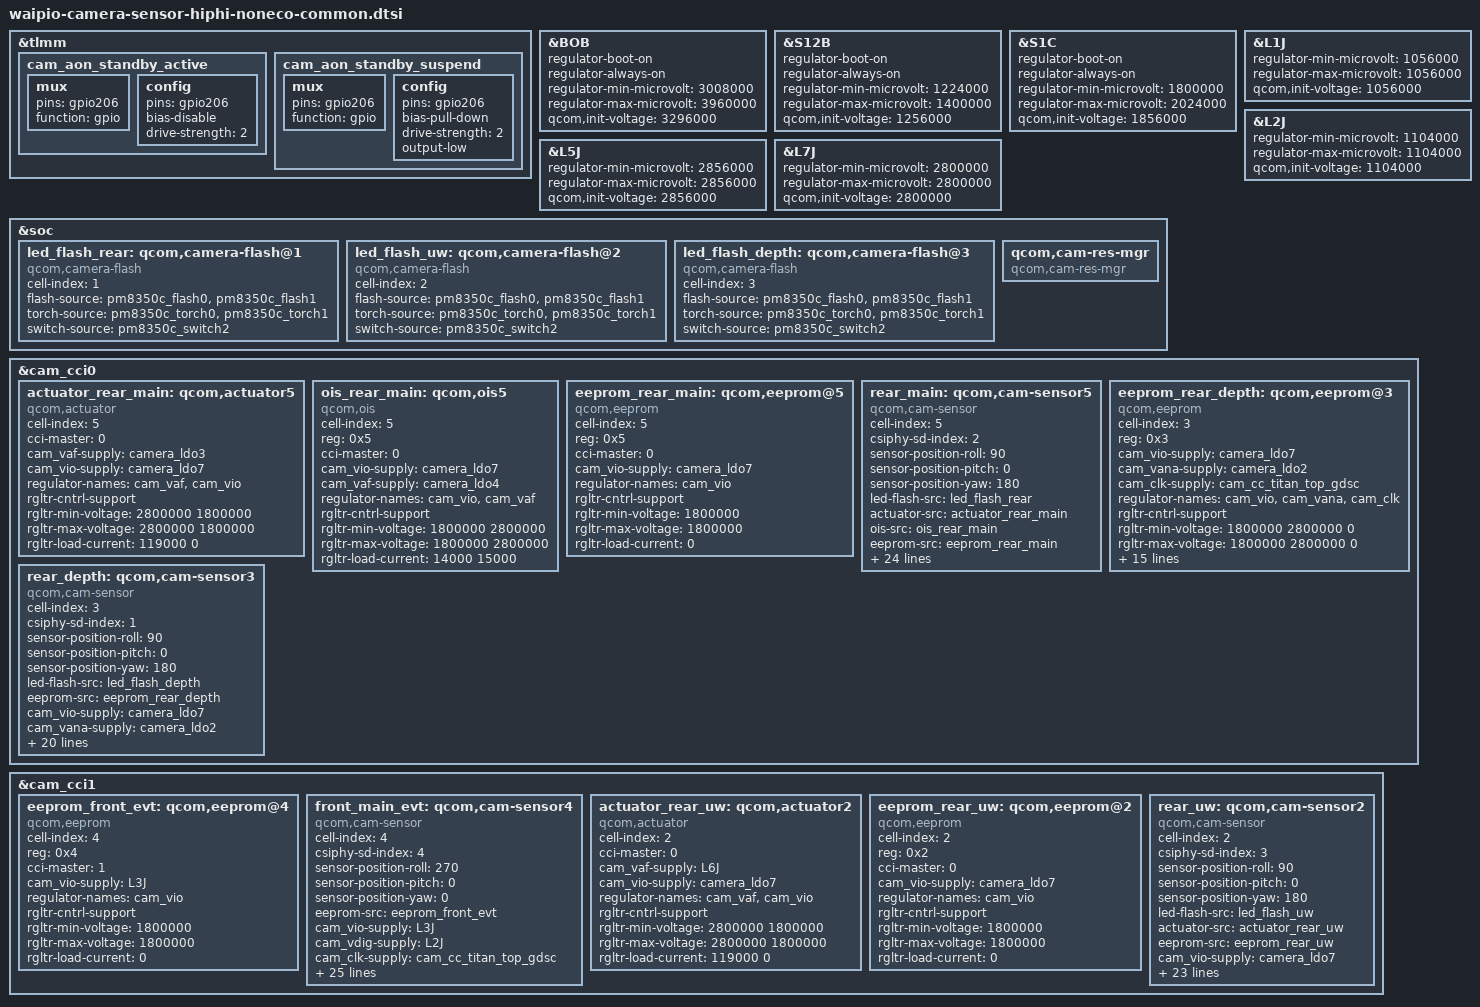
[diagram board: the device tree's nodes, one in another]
/*
   This base is original from "waipio-camera-sensor-mtp.dtsi"
*/
#include <dt-bindings/clock/qcom,camcc-waipio.h>

&tlmm {
	cam_aon_standby_active: cam_aon_standby_active {
		mux {
			pins = "gpio206";
			function = "gpio";
		};

		config {
			pins = "gpio206";
			bias-disable; /* No Pull */
			drive-strength = <2>; /* 2 MA */
		};
	};

	cam_aon_standby_suspend: cam_aon_standby_suspend {
		mux {
			pins = "gpio206";
			function = "gpio";
		};

		config {
			pins = "gpio206";
			bias-pull-down; /* Pull Down */
			drive-strength = <2>; /* 2 MA */
			output-low;
		};
	};
};

&BOB {
	regulator-boot-on;
	regulator-always-on;
	regulator-min-microvolt = <3008000>;
	regulator-max-microvolt = <3960000>;
	qcom,init-voltage = <3296000>;
	status = "ok";
};

&S12B {
	regulator-boot-on;
	regulator-always-on;
	regulator-min-microvolt = <1224000>;
	regulator-max-microvolt = <1400000>;
	qcom,init-voltage = <1256000>;
	status = "ok";
};

&S1C {
	regulator-boot-on;
	regulator-always-on;
	regulator-min-microvolt = <1800000>;
	regulator-max-microvolt = <2024000>;
	qcom,init-voltage = <1856000>;
	status = "ok";
};

&L1J {
	regulator-min-microvolt = <1056000>;
	regulator-max-microvolt = <1056000>;
	qcom,init-voltage = <1056000>;
};

&L2J {
	regulator-min-microvolt = <1104000>;
	regulator-max-microvolt = <1104000>;
	qcom,init-voltage = <1104000>;
};

&L5J {
	regulator-min-microvolt = <2856000>;
	regulator-max-microvolt = <2856000>;
	qcom,init-voltage = <2856000>;
};

&L7J {
	regulator-min-microvolt = <2800000>;
	regulator-max-microvolt = <2800000>;
	qcom,init-voltage = <2800000>;
};

&soc {
	led_flash_rear: qcom,camera-flash@1 {
		cell-index = <1>;
		compatible = "qcom,camera-flash";
		flash-source = <&pm8350c_flash0 &pm8350c_flash1>;
		torch-source = <&pm8350c_torch0 &pm8350c_torch1>;
		switch-source = <&pm8350c_switch2>;
		status = "ok";
	};

	led_flash_uw: qcom,camera-flash@2 {
		cell-index = <2>;
		compatible = "qcom,camera-flash";
		flash-source = <&pm8350c_flash0 &pm8350c_flash1>;
		torch-source = <&pm8350c_torch0 &pm8350c_torch1>;
		switch-source = <&pm8350c_switch2>;
		status = "ok";
	};

	led_flash_depth: qcom,camera-flash@3 {
		cell-index = <3>;
		compatible = "qcom,camera-flash";
		flash-source = <&pm8350c_flash0 &pm8350c_flash1>;
		torch-source = <&pm8350c_torch0 &pm8350c_torch1>;
		switch-source = <&pm8350c_switch2>;
		status = "ok";
	};

	qcom,cam-res-mgr {
		compatible = "qcom,cam-res-mgr";
		status = "ok";
	};
};

&cam_cci0 {
	actuator_rear_main: qcom,actuator5 {
		cell-index = <5>;
		compatible = "qcom,actuator";
		cci-master = <0>;
		cam_vaf-supply = <&camera_ldo3>;
		cam_vio-supply = <&camera_ldo7>;
		regulator-names = "cam_vaf", "cam_vio";
		rgltr-cntrl-support;
		rgltr-min-voltage = <2800000 1800000>;
		rgltr-max-voltage = <2800000 1800000>;
		rgltr-load-current = <119000 0>;
	};

	ois_rear_main: qcom,ois5 {
		cell-index = <5>;
		reg = <0x5>;
		compatible = "qcom,ois";
		cci-master = <0>;
		cam_vio-supply = <&camera_ldo7>;
		cam_vaf-supply = <&camera_ldo4>;
		regulator-names = "cam_vio", "cam_vaf";
		rgltr-cntrl-support;
		rgltr-min-voltage = <1800000 2800000>;
		rgltr-max-voltage = <1800000 2800000>;
		rgltr-load-current = <14000 15000>;
		status = "ok";
	};

	eeprom_rear_main: qcom,eeprom@5 {
		cell-index = <5>;
		reg = <0x5>;
		compatible = "qcom,eeprom";
		cci-master = <0>;
		cam_vio-supply = <&camera_ldo7>;
		regulator-names = "cam_vio";
		rgltr-cntrl-support;
		rgltr-min-voltage = <1800000>;
		rgltr-max-voltage = <1800000>;
		rgltr-load-current = <0>;
	};

	rear_main: qcom,cam-sensor5 {
		cell-index = <5>;
		compatible = "qcom,cam-sensor";
		csiphy-sd-index = <2>;
		sensor-position-roll = <90>;
		sensor-position-pitch = <0>;
		sensor-position-yaw = <180>;
		led-flash-src = <&led_flash_rear>;
		actuator-src = <&actuator_rear_main>;
		ois-src = <&ois_rear_main>;
		eeprom-src = <&eeprom_rear_main>;
		cam_vio-supply = <&camera_ldo7>;
		cam_vdig-supply = <&camera_ldo5>;
		cam_clk-supply = <&cam_cc_titan_top_gdsc>;
		cam_vana-supply = <&camera_ldo1>;
		regulator-names = "cam_vio", "cam_vdig",
			"cam_clk", "cam_vana";
		rgltr-cntrl-support;
		rgltr-min-voltage = <1800000 1100000 0 2800000>;
		rgltr-max-voltage = <1800000 1100000 0 2800000>;
		rgltr-load-current = <3000 675000 0 112000>;
		gpio-no-mux = <0>;
		pinctrl-names = "cam_default", "cam_suspend";
		pinctrl-0 = <&cam_sensor_mclk2_active
			&cam_sensor_active_rst2>;
		pinctrl-1 = <&cam_sensor_mclk2_suspend
			&cam_sensor_suspend_rst2>;
		gpios = <&tlmm 102 0>,
			<&tlmm 117 0>;
		gpio-reset = <1>;
		gpio-req-tbl-num = <0 1>;
		gpio-req-tbl-flags = <1 0>;
		gpio-req-tbl-label = "CAMIF_MCLK2",
					"CAM_RESET2";
		cci-master = <0>;
		clocks = <&clock_camcc CAM_CC_MCLK2_CLK>;
		clock-names = "cam_clk";
		clock-cntl-level = "nominal";
		clock-rates = <24000000>;
		status = "ok";
	};

	eeprom_rear_depth: qcom,eeprom@3 {
		cell-index = <3>;
		reg = <0x3>;
		compatible = "qcom,eeprom";
		cam_vio-supply = <&camera_ldo7>;
		cam_vana-supply = <&camera_ldo2>;
		cam_clk-supply = <&cam_cc_titan_top_gdsc>;
		regulator-names = "cam_vio", "cam_vana", "cam_clk";
		rgltr-cntrl-support;
		rgltr-min-voltage = <1800000 2800000 0>;
		rgltr-max-voltage = <1800000 2800000 0>;
		rgltr-load-current = <20000 90000 0>;
		gpio-no-mux = <0>;
		pinctrl-names = "cam_default", "cam_suspend";
		pinctrl-0 = <&cam_sensor_mclk1_active
				 &cam_sensor_active_rst1>;
		pinctrl-1 = <&cam_sensor_mclk1_suspend
				 &cam_sensor_suspend_rst1>;
		gpios = <&tlmm 101 0>,
			<&tlmm 24 0>;
		gpio-reset = <1>;
		gpio-req-tbl-num = <0 1>;
		gpio-req-tbl-flags = <1 0>;
		gpio-req-tbl-label = "CAMIF_MCLK1",
					"CAM_RESET1";
		cci-master = <1>;
		clocks = <&clock_camcc CAM_CC_MCLK1_CLK>;
		clock-names = "cam_clk";
		clock-cntl-level = "nominal";
		clock-rates = <24000000>;
	};

	rear_depth: qcom,cam-sensor3 {
		cell-index = <3>;
		compatible = "qcom,cam-sensor";
		csiphy-sd-index = <1>;
		sensor-position-roll = <90>;
		sensor-position-pitch = <0>;
		sensor-position-yaw = <180>;
		led-flash-src = <&led_flash_depth>;
		eeprom-src = <&eeprom_rear_depth>;
		cam_vio-supply = <&camera_ldo7>;
		cam_vana-supply = <&camera_ldo2>;
		cam_clk-supply = <&cam_cc_titan_top_gdsc>;
		regulator-names = "cam_vio", "cam_vana", "cam_clk";
		rgltr-cntrl-support;
		rgltr-min-voltage = <1800000 2800000 0>;
		rgltr-max-voltage = <1800000 2800000 0>;
		rgltr-load-current = <20000 90000 0>;
		gpio-no-mux = <0>;
		pinctrl-names = "cam_default", "cam_suspend";
		pinctrl-0 = <&cam_sensor_mclk1_active
				 &cam_sensor_active_rst1>;
		pinctrl-1 = <&cam_sensor_mclk1_suspend
				 &cam_sensor_suspend_rst1>;
		gpios = <&tlmm 101 0>,
			<&tlmm 24 0>;
		gpio-reset = <1>;
		gpio-req-tbl-num = <0 1>;
		gpio-req-tbl-flags = <1 0>;
		gpio-req-tbl-label = "CAMIF_MCLK1",
					"CAM_RESET1";
		cci-master = <1>;
		clocks = <&clock_camcc CAM_CC_MCLK1_CLK>;
		clock-names = "cam_clk";
		clock-cntl-level = "nominal";
		clock-rates = <24000000>;
		status = "ok";
	};
};

&cam_cci1 {
	eeprom_front_evt: qcom,eeprom@4 {
		cell-index = <4>;
		reg = <0x4>;
		compatible = "qcom,eeprom";
		cci-master = <1>;
		cam_vio-supply = <&L3J>;
		regulator-names = "cam_vio";
		rgltr-cntrl-support;
		rgltr-min-voltage = <1800000>;
		rgltr-max-voltage = <1800000>;
		rgltr-load-current = <0>;
	};

	front_main_evt: qcom,cam-sensor4 {
		cell-index = <4>;
		compatible = "qcom,cam-sensor";
		csiphy-sd-index = <4>;
		sensor-position-roll = <270>;
		sensor-position-pitch = <0>;
		sensor-position-yaw = <0>;
		eeprom-src = <&eeprom_front_evt>;
		cam_vio-supply = <&L3J>;
		cam_vdig-supply = <&L2J>;
		cam_clk-supply = <&cam_cc_titan_top_gdsc>;
		cam_vana-supply = <&L5J>;
		regulator-names = "cam_vio", "cam_vdig",
			"cam_clk", "cam_vana";
		rgltr-cntrl-support;
		rgltr-min-voltage = <1800000 1104000 0 2856000>;
		rgltr-max-voltage = <1800000 1104000 0 2856000>;
		rgltr-load-current = <3000 125000 0 95000>;
		gpio-no-mux = <0>;
		pinctrl-names = "cam_default", "cam_suspend";
		pinctrl-0 = <&cam_sensor_mclk4_active
			&cam_sensor_active_rst6
			&cam_aon_standby_active>;
		pinctrl-1 = <&cam_sensor_mclk4_suspend
			&cam_sensor_suspend_rst6
			&cam_aon_standby_suspend>;
		gpios = <&tlmm 104 0>,
			<&tlmm 108 0>,
			<&tlmm 206 0>;
		gpio-reset = <1>;
		gpio-custom1 = <2>;
		gpio-req-tbl-num = <0 1 2>;
		gpio-req-tbl-flags = <1 0 0>;
		gpio-req-tbl-label = "CAMIF_MCLK4",
					"CAM_RESET4",
					"CAM_AON_STANDBY";
		cci-master = <1>;
		clocks = <&clock_camcc CAM_CC_MCLK4_CLK>;
		clock-names = "cam_clk";
		clock-cntl-level = "nominal";
		clock-rates = <24000000>;
		status = "ok";
	};

	actuator_rear_uw: qcom,actuator2 {
		cell-index = <2>;
		compatible = "qcom,actuator";
		cci-master = <0>;
		cam_vaf-supply = <&L6J>;
		cam_vio-supply = <&camera_ldo7>;
		regulator-names = "cam_vaf", "cam_vio";
		rgltr-cntrl-support;
		rgltr-min-voltage = <2800000 1800000>;
		rgltr-max-voltage = <2800000 1800000>;
		rgltr-load-current = <119000 0>;
	};

	eeprom_rear_uw: qcom,eeprom@2 {
		cell-index = <2>;
		reg = <0x2>;
		compatible = "qcom,eeprom";
		cci-master = <0>;
		cam_vio-supply = <&camera_ldo7>;
		regulator-names = "cam_vio";
		rgltr-cntrl-support;
		rgltr-min-voltage = <1800000>;
		rgltr-max-voltage = <1800000>;
		rgltr-load-current = <0>;
	};

	rear_uw: qcom,cam-sensor2 {
		cell-index = <2>;
		compatible = "qcom,cam-sensor";
		csiphy-sd-index = <3>;
		sensor-position-roll = <90>;
		sensor-position-pitch = <0>;
		sensor-position-yaw = <180>;
		led-flash-src = <&led_flash_uw>;
		actuator-src = <&actuator_rear_uw>;
		eeprom-src = <&eeprom_rear_uw>;
		cam_vio-supply = <&camera_ldo7>;
		cam_clk-supply = <&cam_cc_titan_top_gdsc>;
		cam_vana-supply = <&L7J>;
		cam_vdig-supply = <&L1J>;
		regulator-names = "cam_vio", "cam_vana",
			"cam_vdig", "cam_clk";
		rgltr-cntrl-support;
		rgltr-min-voltage = <1800000 2800000 1056000 0>;
		rgltr-max-voltage = <1800000 2800000 1056000 0>;
		rgltr-load-current = <3000 148000 212000 0>;
		gpio-no-mux = <0>;
		pinctrl-names = "cam_default", "cam_suspend";
		pinctrl-0 = <&cam_sensor_mclk3_active
			&cam_sensor_active_rst3>;
		pinctrl-1 = <&cam_sensor_mclk3_suspend
			&cam_sensor_suspend_rst3>;
		gpios = <&tlmm 103 0>,
			<&tlmm 120 0>;
		gpio-reset = <1>;
		gpio-req-tbl-num = <0 1>;
		gpio-req-tbl-flags = <1 0>;
		gpio-req-tbl-label = "CAMIF_MCLK3",
			"CAM_RESET3";
		cci-master = <0>;
		clocks = <&clock_camcc CAM_CC_MCLK3_CLK>;
		clock-names = "cam_clk";
		clock-cntl-level = "nominal";
		clock-rates = <24000000>;
		status = "ok";
	};
};
